# STM32F303 register map
File version: 1.4
CPU: CM4 r1p0, little endian, no MPU, no FPU, 4 interrupt priority bits
Registers are 32-bit, read-write, reset 0x0 unless marked. A register's access mark holds for its fields unless they carry their own. Offsets are from the block's base; [hi:lo] are bit positions; {n}, {i} and the like mark numbered series; 'fields as' and 'values as' point back to an identical list.

## TIM2 — General purpose timer
Base 0x40000000
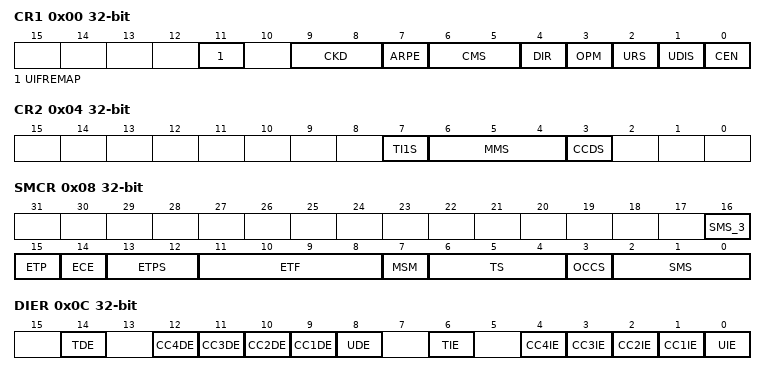
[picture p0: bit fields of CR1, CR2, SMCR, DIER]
0x00 CR1 — control register 1
  [11] UIFREMAP — UIF status bit remapping
  [9:8] CKD — Clock division
    0=Div1 (t_DTS = t_CK_INT); 1=Div2 (t_DTS = 2 × t_CK_INT); 2=Div4 (t_DTS = 4 × t_CK_INT)
  [7] ARPE — Auto-reload preload enable
    0=Disabled (TIMx_APRR register is not buffered); 1=Enabled (TIMx_APRR register is buffered)
  [6:5] CMS — Center-aligned mode selection
    0=EdgeAligned (The counter counts up or down depending on the direction bit); 1=CenterAligned1 (The counter counts up and down alternatively. Output compare interrupt flags are set only when the counter is counting down.); 2=CenterAligned2 (The counter counts up and down alternatively. Output compare interrupt flags are set only when the counter is counting up.); 3=CenterAligned3 (The counter counts up and down alternatively. Output compare interrupt flags are set both when the counter is counting up or down.)
  [4] DIR — Direction
    0=Up (Counter used as upcounter); 1=Down (Counter used as downcounter)
  [3] OPM — One-pulse mode
    0=Disabled (Counter is not stopped at update event); 1=Enabled (Counter stops counting at the next update event (clearing the CEN bit))
  [2] URS — Update request source
    0=AnyEvent (Any of counter overflow/underflow, setting UG, or update through slave mode, generates an update interrupt or DMA request); 1=CounterOnly (Only counter overflow/underflow generates an update interrupt or DMA request)
  [1] UDIS — Update disable
    0=Enabled (Update event enabled); 1=Disabled (Update event disabled)
  [0] CEN — Counter enable
    0=Disabled (Counter disabled); 1=Enabled (Counter enabled)
0x04 CR2 — control register 2
  [7] TI1S — TI1 selection
    0=Normal (The TIMx_CH1 pin is connected to TI1 input); 1=XOR (The TIMx_CH1, CH2, CH3 pins are connected to TI1 input)
  [6:4] MMS — Master mode selection
    0=Reset (The UG bit from the TIMx_EGR register is used as trigger output); 1=Enable (The counter enable signal, CNT_EN, is used as trigger output); 2=Update (The update event is selected as trigger output); 3=ComparePulse (The trigger output send a positive pulse when the CC1IF flag it to be set, as soon as a capture or a compare match occurred); {v}=CompareOC{v-3} (OC{v-3}REF signal is used as trigger output) (v=4..7)
  [3] CCDS — Capture/compare DMA selection
    0=OnCompare (CCx DMA request sent when CCx event occurs); 1=OnUpdate (CCx DMA request sent when update event occurs)
0x08 SMCR — slave mode control register
  [16] SMS_3 — Slave mode selection bit3
  [15] ETP — External trigger polarity
    0=NotInverted (ETR is noninverted, active at high level or rising edge); 1=Inverted (ETR is inverted, active at low level or falling edge)
  [14] ECE — External clock enable
    0=Disabled (External clock mode 2 disabled); 1=Enabled (External clock mode 2 enabled. The counter is clocked by any active edge on the ETRF signal.)
  [13:12] ETPS — External trigger prescaler
    0=Div1 (Prescaler OFF); 1=Div2 (ETRP frequency divided by 2); 2=Div4 (ETRP frequency divided by 4); 3=Div8 (ETRP frequency divided by 8)
  [11:8] ETF — External trigger filter
    0=No filter, sampling is done at fDTS; 1=FCK_INT_N2 (fSAMPLING=fCK_INT, N=2); 2=FCK_INT_N4 (fSAMPLING=fCK_INT, N=4); 3=FCK_INT_N8 (fSAMPLING=fCK_INT, N=8); 4=FDTS_Div2_N6 (fSAMPLING=fDTS/2, N=6); 5=FDTS_Div2_N8 (fSAMPLING=fDTS/2, N=8); 6=FDTS_Div4_N6 (fSAMPLING=fDTS/4, N=6); 7=FDTS_Div4_N8 (fSAMPLING=fDTS/4, N=8); 8=FDTS_Div8_N6 (fSAMPLING=fDTS/8, N=6); 9=FDTS_Div8_N8 (fSAMPLING=fDTS/8, N=8); 10=FDTS_Div16_N5 (fSAMPLING=fDTS/16, N=5); 11=FDTS_Div16_N6 (fSAMPLING=fDTS/16, N=6); 12=FDTS_Div16_N8 (fSAMPLING=fDTS/16, N=8); 13=FDTS_Div32_N5 (fSAMPLING=fDTS/32, N=5); 14=FDTS_Div32_N6 (fSAMPLING=fDTS/32, N=6); 15=FDTS_Div32_N8 (fSAMPLING=fDTS/32, N=8)
  [7] MSM — Master/Slave mode
    0=NoSync (No action); 1=Sync (The effect of an event on the trigger input (TRGI) is delayed to allow a perfect synchronization between the current timer and its slaves (through TRGO). It is useful if we want to synchronize several timers on a single external event.)
  [6:4] TS — Trigger selection
    0=ITR0 (Internal Trigger 0 (ITR0)); 1=ITR1 (Internal Trigger 1 (ITR1)); 2=ITR2 (Internal Trigger 2 (ITR2)); 4=TI1F_ED (TI1 Edge Detector (TI1F_ED)); 5=TI1FP1 (Filtered Timer Input 1 (TI1FP1)); 6=TI2FP2 (Filtered Timer Input 2 (TI2FP2)); 7=ETRF (External Trigger input (ETRF))
  [3] OCCS — OCREF clear selection
  [2:0] SMS — Slave mode selection
    0=Disabled (Slave mode disabled - if CEN = ‘1 then the prescaler is clocked directly by the internal clock.); 1=Encoder mode 1 - Counter counts up/down on TI2FP1 edge depending on TI1FP2 level; 2=Encoder mode 2 - Counter counts up/down on TI1FP2 edge depending on TI2FP1 level; 3=Encoder mode 3 - Counter counts up/down on both TI1FP1 and TI2FP2 edges depending on the level of the other input; 4=Reset Mode - Rising edge of the selected trigger input (TRGI) reinitializes the counter and generates an update of the registers; 5=Gated Mode - The counter clock is enabled when the trigger input (TRGI) is high. The counter stops (but is not reset) as soon as the trigger becomes low. Both start and stop of the counter are controlled.; 6=Trigger Mode - The counter starts at a rising edge of the trigger TRGI (but it is not reset). Only the start of the counter is controlled.; 7=Ext_Clock_Mode (External Clock Mode 1 - Rising edges of the selected trigger (TRGI) clock the counter.)
0x0C DIER — DMA/Interrupt enable register
  [14] TDE — Trigger DMA request enable
    0=Disabled (Trigger DMA request disabled); 1=Enabled (Trigger DMA request enabled)
  [n+8] CC{n}DE (n=1..4) — Capture/Compare {n} DMA request enable
    0=Disabled (CCx DMA request disabled); 1=Enabled (CCx DMA request enabled)
  [8] UDE — Update DMA request enable
    0=Disabled (Update DMA request disabled); 1=Enabled (Update DMA request enabled)
  [6] TIE — Trigger interrupt enable
    0=Disabled (Trigger interrupt disabled); 1=Enabled (Trigger interrupt enabled)
  [n] CC{n}IE (n=1..4) — Capture/Compare {n} interrupt enable
    0=Disabled (CCx interrupt disabled); 1=Enabled (CCx interrupt enabled)
  [0] UIE — Update interrupt enable
    0=Disabled (Update interrupt disabled); 1=Enabled (Update interrupt enabled)
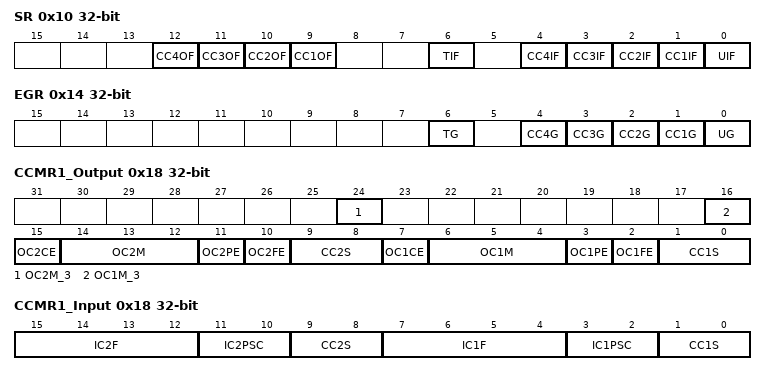
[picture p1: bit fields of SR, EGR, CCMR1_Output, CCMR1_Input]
0x10 SR — status register
  [12] CC4OF — Capture/Compare 4 overcapture flag
    on read: 1=Overcapture (The counter value has been captured in TIMx_CCRx register while CCxIF flag was already set) | on write: 0=Clear flag
  [11] CC3OF — Capture/Compare 3 overcapture flag
    values as CC4OF
  [10] CC2OF — Capture/compare 2 overcapture flag
    values as CC4OF
  [9] CC1OF — Capture/Compare 1 overcapture flag
    values as CC4OF
  [6] TIF — Trigger interrupt flag
    on read: 0=No trigger event occurred; 1=Trigger interrupt pending | on write: 0=Clear flag
  [4] CC4IF — Capture/Compare 4 interrupt flag
    on read: 1=Match (If CC1 is an output: The content of the counter TIMx_CNT matches the content of the TIMx_CCR1 register. If CC1 is an input: The counter value has been captured in TIMx_CCR1 register.) | on write: 0=Clear flag
  [3] CC3IF — Capture/Compare 3 interrupt flag
    values as CC4IF
  [2] CC2IF — Capture/Compare 2 interrupt flag
    values as CC4IF
  [1] CC1IF — Capture/compare 1 interrupt flag
    values as CC4IF
  [0] UIF — Update interrupt flag
    0=Clear (No update occurred); 1=UpdatePending (Update interrupt pending.)
0x14 EGR wo — event generation register
  [6] TG — Trigger generation
    on write: 1=Trigger (The TIF flag is set in TIMx_SR register. Related interrupt or DMA transfer can occur if enabled.)
  [n] CC{n}G (n=1..4) — Capture/compare {n} generation
    on write: 1=Trigger (If CC1 is an output: CC1IF flag is set, Corresponding interrupt or DMA request is sent if enabled. If CC1 is an input: The current value of the counter is captured in TIMx_CCR1 register.)
  [0] UG — Update generation
    1=Update (Re-initializes the timer counter and generates an update of the registers.)
0x18 CCMR1_Output — capture/compare mode register 1 (output mode)
  [24] OC2M_3 — Output compare 2 mode bit 3
    0=Normal output compare mode (modes 0-7); 1=Extended output compare mode (modes 7-15)
  [16] OC1M_3 — Output compare 1 mode bit 3
    values as OC2M_3
  [15] OC2CE — Output compare 2 clear enable
  [14:12] OC2M — Output compare 2 mode
    0=Frozen (The comparison between the output compare register TIMx_CCRy and the counter TIMx_CNT has no effect on the outputs / OpmMode1: Retriggerable OPM mode 1 - In up-counting mode, the channel is active until a trigger event is detected (on TRGI signal). In down-counting mode, the channel is inactive); 1=ActiveOnMatch (Set channel to active level on match. OCyREF signal is forced high when the counter matches the capture/compare register / OpmMode2: Inversely to OpmMode1); 2=InactiveOnMatch (Set channel to inactive level on match. OCyREF signal is forced low when the counter matches the capture/compare register / Reserved); 3=Toggle (OCyREF toggles when TIMx_CNT=TIMx_CCRy / Reserved); 4=ForceInactive (OCyREF is forced low / CombinedPwmMode1: OCyREF has the same behavior as in PWM mode 1. OCyREFC is the logical OR between OC1REF and OC2REF); 5=ForceActive (OCyREF is forced high / CombinedPwmMode2: OCyREF has the same behavior as in PWM mode 2. OCyREFC is the logical AND between OC1REF and OC2REF); 6=PwmMode1 (In upcounting, channel is active as long as TIMx_CNT<TIMx_CCRy else inactive. In downcounting, channel is inactive as long as TIMx_CNT>TIMx_CCRy else active / AsymmetricPwmMode1: OCyREF has the same behavior as in PWM mode 1. OCyREFC outputs OC1REF when the counter is counting up, OC2REF when it is counting down); 7=PwmMode2 (Inversely to PwmMode1 / AsymmetricPwmMode2: Inversely to AsymmetricPwmMode1)
  [11] OC2PE — Output compare 2 preload enable
    0=Disabled (Preload register on CCR2 disabled. New values written to CCR2 are taken into account immediately); 1=Enabled (Preload register on CCR2 enabled. Preload value is loaded into active register on each update event)
  [10] OC2FE — Output compare 2 fast enable
  [9:8] CC2S — Capture/Compare 2 selection
    0=Output (CC2 channel is configured as output)
  [7] OC1CE — Output compare 1 clear enable
  [6:4] OC1M — Output compare 1 mode
    values as OC2M
  [3] OC1PE — Output compare 1 preload enable
    0=Disabled (Preload register on CCR1 disabled. New values written to CCR1 are taken into account immediately); 1=Enabled (Preload register on CCR1 enabled. Preload value is loaded into active register on each update event)
  [2] OC1FE — Output compare 1 fast enable
  [1:0] CC1S — Capture/Compare 1 selection
    0=Output (CC1 channel is configured as output)
0x18 CCMR1_Input (alternate view of CCMR1_Output) — capture/compare mode register 1 (input mode)
  [15:12] IC2F — Input capture 2 filter
  [11:10] IC2PSC — Input capture 2 prescaler
  [9:8] CC2S — Capture/compare 2 selection
    1=TI2 (CC2 channel is configured as input, IC2 is mapped on TI2); 2=TI1 (CC2 channel is configured as input, IC2 is mapped on TI1); 3=TRC (CC2 channel is configured as input, IC2 is mapped on TRC)
  [7:4] IC1F — Input capture 1 filter
    values as SMCR.ETF
  [3:2] IC1PSC — Input capture 1 prescaler
  [1:0] CC1S — Capture/Compare 1 selection
    1=TI1 (CC1 channel is configured as input, IC1 is mapped on TI1); 2=TI2 (CC1 channel is configured as input, IC1 is mapped on TI2); 3=TRC (CC1 channel is configured as input, IC1 is mapped on TRC)
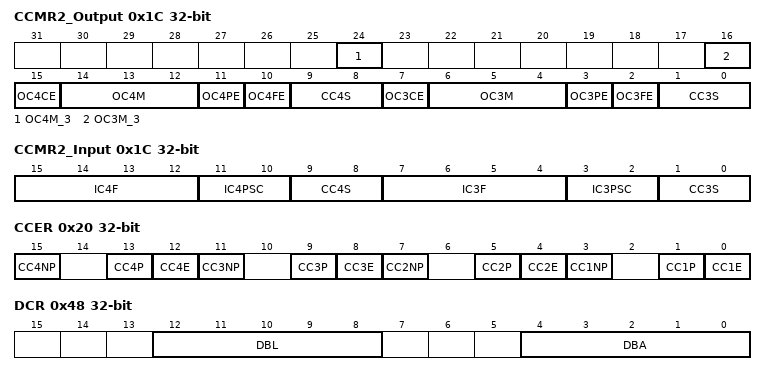
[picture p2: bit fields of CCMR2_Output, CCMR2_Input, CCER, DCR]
0x1C CCMR2_Output — capture/compare mode register 2 (output mode)
  [24] OC4M_3 — Output compare 4 mode bit3
    values as CCMR1_Output.OC2M_3
  [16] OC3M_3 — Output compare 3 mode bit3
    values as CCMR1_Output.OC2M_3
  [15] OC4CE — Output compare 4 clear enable
  [14:12] OC4M — Output compare 4 mode
    values as CCMR1_Output.OC2M
  [11] OC4PE — Output compare 4 preload enable
    0=Disabled (Preload register on CCR4 disabled. New values written to CCR4 are taken into account immediately); 1=Enabled (Preload register on CCR4 enabled. Preload value is loaded into active register on each update event)
  [10] OC4FE — Output compare 4 fast enable
  [9:8] CC4S — Capture/Compare 4 selection
    0=Output (CC4 channel is configured as output)
  [7] OC3CE — Output compare 3 clear enable
  [6:4] OC3M — Output compare 3 mode
    values as CCMR1_Output.OC2M
  [3] OC3PE — Output compare 3 preload enable
    0=Disabled (Preload register on CCR3 disabled. New values written to CCR3 are taken into account immediately); 1=Enabled (Preload register on CCR3 enabled. Preload value is loaded into active register on each update event)
  [2] OC3FE — Output compare 3 fast enable
  [1:0] CC3S — Capture/Compare 3 selection
    0=Output (CC3 channel is configured as output)
0x1C CCMR2_Input (alternate view of CCMR2_Output) — capture/compare mode register 2 (input mode)
  [15:12] IC4F — Input capture 4 filter
  [11:10] IC4PSC — Input capture 4 prescaler
  [9:8] CC4S — Capture/Compare 4 selection
    1=TI4 (CC4 channel is configured as input, IC4 is mapped on TI4); 2=TI3 (CC4 channel is configured as input, IC4 is mapped on TI3); 3=TRC (CC4 channel is configured as input, IC4 is mapped on TRC)
  [7:4] IC3F — Input capture 3 filter
  [3:2] IC3PSC — Input capture 3 prescaler
  [1:0] CC3S — Capture/Compare 3 selection
    1=TI3 (CC3 channel is configured as input, IC3 is mapped on TI3); 2=TI4 (CC3 channel is configured as input, IC3 is mapped on TI4); 3=TRC (CC3 channel is configured as input, IC3 is mapped on TRC)
0x20 CCER — capture/compare enable register
  [15] CC4NP — Capture/Compare 3 output Polarity
  [13] CC4P — Capture/Compare 3 output Polarity
  [4n-4] CC{n}E (n=1..4) — Capture/Compare {n} output enable
  [11] CC3NP — Capture/Compare 3 output Polarity
  [9] CC3P — Capture/Compare 3 output Polarity
  [7] CC2NP — Capture/Compare 2 output Polarity
  [5] CC2P — Capture/Compare 2 output Polarity
  [3] CC1NP — Capture/Compare 1 output Polarity
  [1] CC1P — Capture/Compare 1 output Polarity
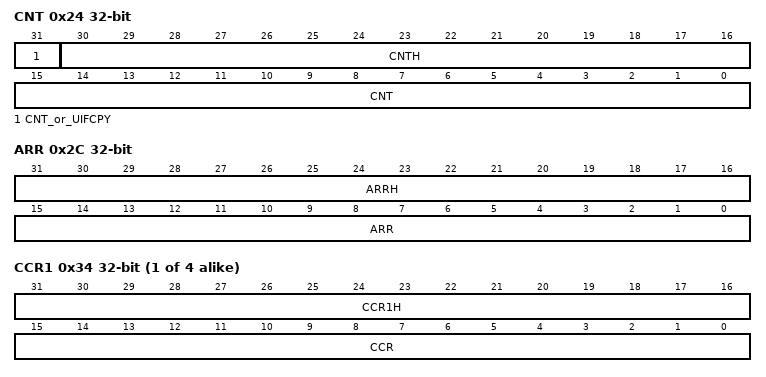
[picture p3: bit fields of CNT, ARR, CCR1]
0x24 CNT — counter
  [31:0] CNT — Low counter value
0x28 PSC — prescaler
  [15:0] PSC — Prescaler value
0x2C ARR — auto-reload register
  [31:0] ARR — Low Auto-reload value
{0x30+4i} CCR{i} (i=1..4) — capture/compare register
  [31:0] CCR — Capture/Compare value
0x48 DCR — DMA control register
  [12:8] DBL range 0..18 — DMA burst length
  [4:0] DBA — DMA base address
0x4C DMAR — DMA address for full transfer
  [15:0] DMAB — DMA register for burst accesses

## TIM3 — General purpose timer
Base 0x40000400
Same registers: TIM4 0x40000800
Registers as TIM2; these are added or differ:
0x24 CNT — counter
  [31] CNT_or_UIFCPY — if IUFREMAP=0 than CNT with read write access else UIFCPY with read only access
  [30:16] CNTH — High counter value
  [15:0] CNT — Counter value
0x2C ARR — auto-reload register
  [31:16] ARRH — High Auto-reload value
  [15:0] ARR — Auto-reload value
{0x30+4i} CCR{i} (i=1..4) — capture/compare register
  [31:16] CCR1H — High Capture/Compare 1 value (on TIM2)
  [15:0] CCR — Capture/Compare value
